AUTOSAR XML (schema 321)
package /ComponentType
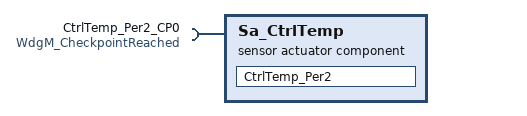
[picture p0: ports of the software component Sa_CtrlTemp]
  sensor actuator software component type Sa_CtrlTemp
    require port CtrlTemp_Per2_CP0: client-com-spec=CheckpointReached, required-interface=WdgM_CheckpointReached
  internal behavior Sa_CtrlTemp_InternalBehavior: component=Sa_CtrlTemp, port-api-option{enable-take-address=false, indirect-api=false, port=CtrlTemp_Per2_CP0}
    runnable CtrlTemp_Per2
      sync call SC_CtrlTemp_Per2_CP0_CheckpointReached: operation=CtrlTemp_Per2_CP0.CheckpointReached, timeout=0
  swc implementation Sa_CtrlTemp_Implementation: behavior=Sa_CtrlTemp_InternalBehavior
    code-descriptors:
      code Code: type=SRC
package /PortInterface
  client server interface WdgM_CheckpointReached: is-service=true
    operation CheckpointReached: possible-error=E_NOT_OK  # Indicates to the Watchdog Manager that a Checkpoint within a Supervised Entity has been reached.
    error E_NOT_OK: error-code=1
